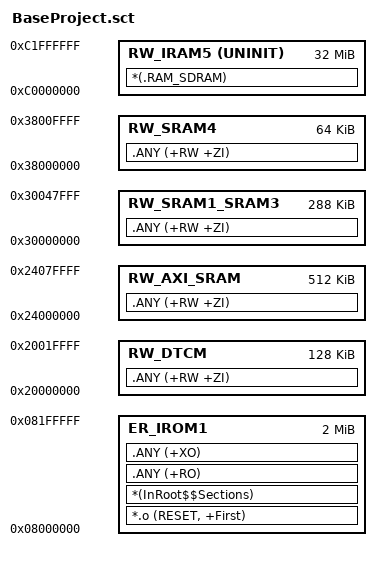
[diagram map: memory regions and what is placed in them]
; *************************************************************
; *** Scatter-Loading Description File generated by uVision ***
; *************************************************************

; 这是整个程序的加载区域，通常对应Flash存储器
LR_IROM1 0x08000000 0x00200000  {    ; load region size_region (2MB)
  ; 存放程序的只读代码和常量
  ER_IROM1 0x08000000 0x00200000  {  ; load address = execution address (2MB)
   *.o (RESET, +First)               ; 所有目标文件的RESET段，放在最前面(复位向量)
   *(InRoot$$Sections)               ; 根区域必要的特殊段(如异常向量表)
   .ANY (+RO)                        ; 任何文件的只读代码和常量(RO段)
   .ANY (+XO)                        ; 任何文件的可执行代码(XO段)
  }
  
  ; DTCM是内核紧密耦合的数据存储器，访问速度快 (128KB)
  RW_DTCM 0x20000000 0x00020000  {  ; RW data 
   .ANY (+RW +ZI)                     ; 任何文件的读写数据(RW)和未初始化数据(ZI)
   ;*(.RAM_D0)	;段选择器，若不手动选择，则完全不会被分配到此
  }
  
  ; AXI接口的SRAM，通常用于高性能数据访问 (512KB)
  RW_AXI_SRAM 0x24000000 0x00080000  {
   .ANY (+RW +ZI)                     ; 任何文件的读写数据和未初始化数据
   ;*(.RAM_D1)	;段选择器，若不手动选择，则完全不会被分配到此
  }
  
  ; 片上静态存储器区域1-3 (288KB)
  RW_SRAM1_SRAM3 0x30000000 0x00048000  {
   .ANY (+RW +ZI)                     ; 任何文件的读写数据和未初始化数据
   ;*(.RAM_D2)	;段选择器，若不手动选择，则完全不会被分配到此
  }
  
  ; 片上静态存储器区域4 (64KB)
  RW_SRAM4 0x38000000 0x00010000  {
   .ANY (+RW +ZI)                     ; 任何文件的读写数据和未初始化数据
   ;*(.RAM_D3)	;段选择器，若不手动选择，则完全不会被分配到此
  }
  
  ; 片外静态存储器区域 (32MB)
  RW_IRAM5 0xC0000000 UNINIT 0x02000000  {
   *(.RAM_SDRAM)
  }
}

; 段选择器使用案例：
; __attribute__((section (".RAM_D1"))) uint32_t Buf[10];
; __attribute__((section (".RAM_D2"))) uint16_t Count;
;
; 若没使用段选择器，其实也可以使用__attribute__来选择某一内存起始地址进行存储，不过的话就是不方便管理。

; 若没有使用段选择器，那么就会按照分散加载文件中内存区域的定义顺序依次分配，
; 直到前面的区域被占满后才会 “溢出” 到后面的区域。
;

